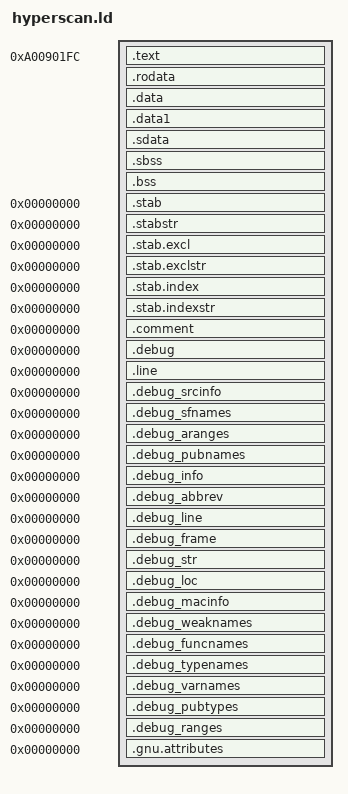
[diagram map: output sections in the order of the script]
OUTPUT_FORMAT("elf32-littlescore")
OUTPUT_ARCH(score7)
ENTRY(_start)
SECTIONS
{

  . = 0xA00901FC;

  .text :
  {
    KEEP( *(.crt0) )
    *(.text)
  }
  .rodata         : { *(.rodata .rodata.* .gnu.linkonce.r.*) }
  .data : { *(.data) }
  .data1          : { *(.data1) }
  . = .;
  _gp = ALIGN(16) + 0x3ff0;
  .sdata          :
  {
    _sdata_begin = .;
    *(.sdata .sdata.* .gnu.linkonce.s.*)
  }
  . = ALIGN(4);
  __bss_start__ = ALIGN(4);
  .sbss           :
  {
    *(.sbss .sbss.* .gnu.linkonce.sb.*)
    *(.scommon)
  }
  .bss            :
  {
   *(.bss .bss.* .gnu.linkonce.b.*)
   *(COMMON)
   /* Align here to ensure that the .bss section occupies space up to
      _end.  Align after .bss to ensure correct alignment even if the
      .bss section disappears because there are no input sections.
      FIXME: Why do we need it? When there is no .bss section, we do not
      pad the .data section.  */
   . = ALIGN(. != 0 ? 32 / 8 : 1);
  }
  __bss_end__ = .; __end__ = .;
  . = ALIGN(32 / 8);

  __bss_wsize__ = ( __bss_end__ - __bss_start__ ) / 4;

  /* Stabs debugging sections.  */
  .stab          0 : { *(.stab) }
  .stabstr       0 : { *(.stabstr) }
  .stab.excl     0 : { *(.stab.excl) }
  .stab.exclstr  0 : { *(.stab.exclstr) }
  .stab.index    0 : { *(.stab.index) }
  .stab.indexstr 0 : { *(.stab.indexstr) }
  .comment       0 : { *(.comment) }
  /* DWARF debug sections.
     Symbols in the DWARF debugging sections are relative to the beginning
     of the section so we begin them at 0.  */
  /* DWARF 1 */
  .debug          0 : { *(.debug) }
  .line           0 : { *(.line) }
  /* GNU DWARF 1 extensions */
  .debug_srcinfo  0 : { *(.debug_srcinfo) }
  .debug_sfnames  0 : { *(.debug_sfnames) }
  /* DWARF 1.1 and DWARF 2 */
  .debug_aranges  0 : { *(.debug_aranges) }
  .debug_pubnames 0 : { *(.debug_pubnames) }
  /* DWARF 2 */
  .debug_info     0 : { *(.debug_info .gnu.linkonce.wi.*) }
  .debug_abbrev   0 : { *(.debug_abbrev) }
  .debug_line     0 : { *(.debug_line) }
  .debug_frame    0 : { *(.debug_frame) }
  .debug_str      0 : { *(.debug_str) }
  .debug_loc      0 : { *(.debug_loc) }
  .debug_macinfo  0 : { *(.debug_macinfo) }
  /* SGI/MIPS DWARF 2 extensions */
  .debug_weaknames 0 : { *(.debug_weaknames) }
  .debug_funcnames 0 : { *(.debug_funcnames) }
  .debug_typenames 0 : { *(.debug_typenames) }
  .debug_varnames  0 : { *(.debug_varnames) }
  /* DWARF 3 */
  .debug_pubtypes 0 : { *(.debug_pubtypes) }
  .debug_ranges   0 : { *(.debug_ranges) }
  .gnu.attributes 0 : { KEEP (*(.gnu.attributes)) }
  /DISCARD/ : { *(.note.GNU-stack) *(.gnu_debuglink) *(.gnu.lto_*) }
}
